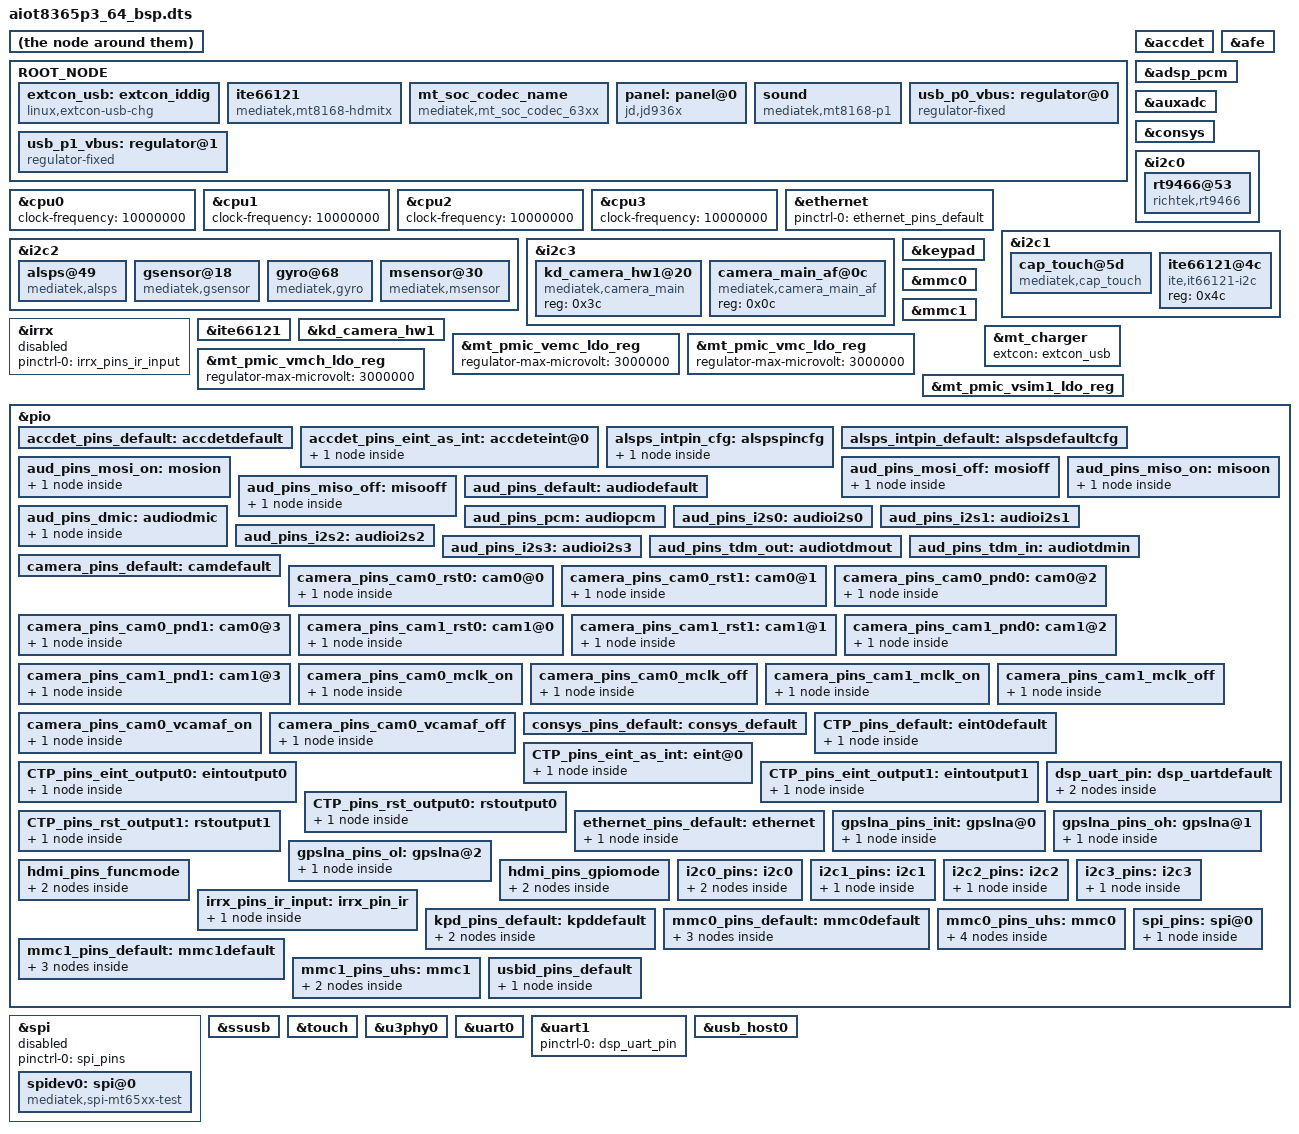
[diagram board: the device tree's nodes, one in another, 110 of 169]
/*
 * Copyright (c) 2018 MediaTek Inc.
 *
 * This program is free software; you can redistribute it and/or modify
 * it under the terms of the GNU General Public License version 2 as
 * published by the Free Software Foundation.
 *
 * This program is distributed in the hope that it will be useful,
 * MERCHANTABILITY or FITNESS FOR A PARTICULAR PURPOSE.  See the
 * GNU General Public License for more details.
 */

#include <generated/autoconf.h>
/dts-v1/;

/plugin/;
#include <dt-bindings/clock/mt8168-clk.h>
#include <dt-bindings/interrupt-controller/irq.h>
#include <dt-bindings/interrupt-controller/arm-gic.h>
#include <dt-bindings/pinctrl/mt8168-pinfunc.h>
#include <dt-bindings/gpio/gpio.h>
#include <dt-bindings/phy/phy.h>
#define ROOT_NODE &odm

ROOT_NODE {
	extcon_usb: extcon_iddig {
		compatible = "linux,extcon-usb-chg";
		id-gpio = <&pio 23 GPIO_ACTIVE_HIGH>;
		pinctrl-names = "default";
		pinctrl-0 = <&usbid_pins_default>;
	};

	ite66121: ite66121 {
		compatible = "mediatek,mt8168-hdmitx";
	};

	mt_soc_codec_name: mt_soc_codec_name {
		compatible = "mediatek,mt_soc_codec_63xx";
		use_hp_depop_flow = <0>; /* select 1: use, 0: not use */
		use_ul_260k = <0>; /* select 1: use, 0: not use */
	};

	panel: panel@0 {
		compatible = "jd,jd936x";
		gpio_lcd_pwr = <&pio 68 0>;
		gpio_lcd_rst = <&pio 20 0>;
		gpio_lcd_stb = <&pio 21 0>;
		reg-lcm-supply = <&mt_pmic_vsim1_ldo_reg>;
	};

	sound: sound {
		compatible = "mediatek,mt8168-p1";
		mediatek,platform = <&afe>;
		mediatek,adsp-platform = <&adsp_pcm>;
		pinctrl-names = "aud_mosi_on",
			"aud_mosi_off",
			"aud_miso_on",
			"aud_miso_off",
			"default",
			"aud_dmic",
			"aud_pcm",
			"aud_i2s0",
			"aud_i2s1",
			"aud_i2s2",
			"aud_i2s3",
			"aud_tdm_out",
			"aud_tdm_in";
		pinctrl-0 = <&aud_pins_mosi_on>;
		pinctrl-1 = <&aud_pins_mosi_off>;
		pinctrl-2 = <&aud_pins_miso_on>;
		pinctrl-3 = <&aud_pins_miso_off>;
		pinctrl-4 = <&aud_pins_default>;
		pinctrl-5 = <&aud_pins_dmic>;
		pinctrl-6 = <&aud_pins_pcm>;
		pinctrl-7 = <&aud_pins_i2s0>;
		pinctrl-8 = <&aud_pins_i2s1>;
		pinctrl-9 = <&aud_pins_i2s2>;
		pinctrl-10 = <&aud_pins_i2s3>;
		pinctrl-11 = <&aud_pins_tdm_out>;
		pinctrl-12 = <&aud_pins_tdm_in>;
		ext-amp1-gpio = <&pio 22 0>;
		ext-amp2-gpio = <&pio 22 0>;
		status = "okay";
	};

	usb_p0_vbus: regulator@0 {
		compatible = "regulator-fixed";
		regulator-name = "vbus0";
		regulator-min-microvolt = <5000000>;
		regulator-max-microvolt = <5000000>;
		gpio = <&pio 28 GPIO_ACTIVE_HIGH>;
		enable-active-high;
	};

	usb_p1_vbus: regulator@1 {
		compatible = "regulator-fixed";
		regulator-name = "vbus1";
		regulator-min-microvolt = <5000000>;
		regulator-max-microvolt = <5000000>;
		gpio = <&pio 134 GPIO_ACTIVE_HIGH>;
		enable-active-high;
		regulator-always-on;
	};
};

&accdet {
	accdet-mic-vol = <6>;
	headset-mode-setting = <0x500 0x500 1 0x1f0 0x800 0x800 0x20 0x44>;
	accdet-plugout-debounce = <1>;
	accdet-mic-mode = <1>;
	headset-eint-level-pol = <4>;
	headset-three-key-threshold = <0 80 220 400>;
	headset-three-key-threshold-CDD = <0 121 192 600>;
	headset-four-key-threshold = <0 58 121 192 400>;
	pinctrl-names = "default", "state_eint_as_int";
	pinctrl-0 = <&accdet_pins_default>;
	pinctrl-1 = <&accdet_pins_eint_as_int>;
	status = "okay";
};

&afe {
	mediatek,dl1-use-sram = <0x11221000 0x5000>;
	mediatek,dmic-iir-on = <1>;
	mediatek,dmic-irr-mode = <5>;
	mediatek,dmic-two-wire-mode = <1>;
	status = "okay";
};

&adsp_pcm {
	status = "okay";
};

&auxadc {
	status = "okay";
};

&consys {
	pinctrl-names = "default", "gps_lna_state_init",
			"gps_lna_state_oh", "gps_lna_state_ol";
	pinctrl-0 = <&consys_pins_default>;
	pinctrl-1 = <&gpslna_pins_init>;
	pinctrl-2 = <&gpslna_pins_oh>;
	pinctrl-3 = <&gpslna_pins_ol>;
	status = "okay";
};

&cpu0 {
	clock-frequency = <10000000>;
};

&cpu1 {
	clock-frequency = <10000000>;
};

&cpu2 {
	clock-frequency = <10000000>;
};

&cpu3 {
	clock-frequency = <10000000>;
};

&ethernet {
	status = "okay";
	pinctrl-names = "default";
	pinctrl-0 = <&ethernet_pins_default>;
};

&i2c0 {
	pinctrl-names = "default";
	pinctrl-0 = <&i2c0_pins>;
	clock-frequency = <100000>;
	status = "okay";
	rt9466@53 {
		compatible = "richtek,rt9466";
		reg = <0x53>;
		interrupt-parent = <&pio>;
		interrupts = <124 IRQ_TYPE_EDGE_FALLING>;
		rt-interrupt-names = "wdtmri", "chg_mivr", "chg_aiclmeasi",
			"chg_statci", "pwr_rdy";
		status = "okay";
		/*
		 * Charger name
		 * Main charger: primary_chg
		 * Slave charger: secondary_chg
		 */
		charger_name = "primary_chg";
		ichg = <2000000>; /* uA */
		aicr = <500000>;  /* uA */
		mivr = <4400000>; /* uV */
		cv = <4350000>;   /* uV */
		ieoc = <250000>;  /* uA */
		safety_timer = <12>;  /* hour */
		ircmp_resistor = <80000>; /* uohm */
		ircmp_vclamp = <96000>;  /* uV */
		en_te;
		/* en_wdt; */ /* remove it to support remote OTG wakeup */
		/* en_jeita; */
		/* en_irq_pulse; */
		/* ceb_invert; */
	};
};

&i2c1 {
	pinctrl-names = "default";
	pinctrl-0 = <&i2c1_pins>;
	clock-frequency = <100000>;
	status = "okay";

	cap_touch@5d {
		compatible = "mediatek,cap_touch";
		reg = <0x5d>;
		interrupt-parent = <&pio>;
		interrupts = <126 IRQ_TYPE_EDGE_RISING>;
		int-gpio = <&pio 126 0>;
		rst-gpio = <&pio 127 0>;
		status = "okay";
	};

	ite66121@4c {
		compatible = "ite,it66121-i2c";
		reg = <0x4c>;
		status = "okay";
	};
};

&i2c2 {
	pinctrl-names = "default";
	pinctrl-0 = <&i2c2_pins>;
	clock-frequency = <100000>;
	status = "okay";

	alsps@49 {
		compatible = "mediatek,alsps";
		pinctrl-names = "pin_default", "pin_cfg";
		pinctrl-0 = <&alsps_intpin_default>;
		pinctrl-1 = <&alsps_intpin_cfg>;

		interrupt-parent = <&pio>;
		interrupts = <117 IRQ_TYPE_LEVEL_LOW>;
		debounce = <117 0>;

		i2c_num = <2>;
		reg = <0x49>;
		polling_mode_ps = <0>;
		polling_mode_als = <1>;
		is_batch_supported_ps = <0>;
		is_batch_supported_als = <0>;
		is_batch_supported = <0>;
		power_id = <0xffff>;
		power_vol = <0>;
		firlen = <16>;

		/* epl259x */
		epl259x_addr = <0x49 0 0 0>;
		epl259x_level = <20 45 70 90 150 300 500 700 1150 2250 4500
				 8000 15000 30000 50000>;
		epl259x_value = <10 30 60 80 100 200 400 600 800 1500 3000
				 6000 10000 20000 40000 60000>;
		epl259x_thld_high =  <800>;
		epl259x_thld_low =  <500>;

		/* stk3x1x */
		stk3x1x_addr = <0x48 0 0 0>;
		stk3x1x_level = <5 9 36 59 82 132 205 273 500 845 1136 1545
				 2364 4655 6982>;
		stk3x1x_value = <30 40 80 130 180 290 450 600 1100 1860 2500
				 3400 5200 10240 10240 10240>;
		stk3x1x_thld_high = <1700>;
		stk3x1x_thld_low = <1500>;

		/* stk3x3x */
		stk3x3x_addr = <0x57 0 0 0>;
		stk3x3x_level = <10 80 160 240 400 560 700 900 1100 1300 1500
				 2364 3000 4655 6982>;
		stk3x3x_value = <0 80 160 260 450 600 750 1000 1250 1450 1700
				 2600 3300 5120 7680 10240>;
		stk3x3x_thld_high = <1700>;
		stk3x3x_thld_low = <1500>;

		status = "okay";
	};

	gsensor@18 {
		compatible = "mediatek,gsensor";
		reg = <0x18>;
		i2c_num = <2>;
		power_id = <0xffff>;
		power_vol = <0>;
		firlen = <16>;
		is_batch_supported = <0>;

		/* stk8baxx */
		stk8baxx_addr = <0x18 0 0 0>;
		stk8baxx_direction = <3>;

		/* mc34xx */
		mc34xx_addr = <0x4c 0 0 0>;
		mc34xx_direction = <3>;

		/* mpu6050g */
		mpu6050g_addr = <0x68 0 0 0>;
		mpu6050g_direction = <4>;

		status = "okay";
	};

	gyro@68 {
		compatible = "mediatek,gyro";
		reg = <0x68>;
		i2c_num = <2>;
		power_id = <0xffff>;
		power_vol = <0>;
		firlen = <0>;
		is_batch_supported = <0>;

		/* mpu6050gy */
		mpu6050gy_addr = <0x68 0 0 0>;
		mpu6050gy_direction = <4>;

		status = "okay";
	};

	msensor@30 {
		compatible = "mediatek,msensor";
		reg = <0x30>;
		i2c_num = <2>;
		power_id = <0xffff>;
		power_vol = <0>;
		is_batch_supported = <0>;

		/* mmc3416x */
		mmc3416x_addr = <0x30 0 0 0>;
		mmc3416x_direction = <2>;

		/* mmc3630x */
		mmc3630x_addr = <0x30 0 0 0>;
		mmc3630x_direction = <2>;

		status = "okay";
	};
};

&i2c3 {
	pinctrl-names = "default";
	pinctrl-0 = <&i2c3_pins>;
	clock-frequency = <100000>;
	status = "okay";

	kd_camera_hw1@20 {
		compatible = "mediatek,camera_main";
		reg = <0x3c>;
	};

	camera_main_af@0c {
		compatible = "mediatek,camera_main_af";
		reg = <0x0c>;
	};
};

&irrx {
	pinctrl-names = "default";
	pinctrl-0 = <&irrx_pins_ir_input>;
	status = "disabled";
};

&ite66121 {
	pinctrl-names = "hdmi_poweron", "hdmi_poweroff";
	pinctrl-0 = <&hdmi_pins_funcmode>;
	pinctrl-1 = <&hdmi_pins_gpiomode>;
	hdmi_power_gpios = <&pio 79 0>;
	not_use_pmic_supply;
	status = "okay";
};

&keypad {
	pinctrl-names = "default";
	pinctrl-0 = <&kpd_pins_default>;
	status = "okay";
	mediatek,kpd-key-debounce = <1024>;
	mediatek,kpd-sw-pwrkey = <116>;
	mediatek,kpd-hw-pwrkey = <1>;
	mediatek,kpd-sw-rstkey  = <115>;
	mediatek,kpd-hw-rstkey = <3>;
	mediatek,kpd-use-extend-type = <0>;
	/*HW Keycode [0~3] -> Linux Keycode*/
	mediatek,kpd-hw-map-num = <72>;
	mediatek,kpd-hw-init-map =
			<114 0 0 0 0 0 0 0 0 0 0 0 0
			 0 0 0 0 0 0 0 0 0 0 0 0 0 0 0 0 0 0 0 0 0 0 0 0
			 0 0 0 0 0 0 0 0 0 0 0 0 0 0 0 0 0 0 0 0 0 0 0 0
			 0 0 0 0 0 0 0 0 0 0 0 >;
	mediatek,kpd-pwrkey-eint-gpio = <0>;
	mediatek,kpd-pwkey-gpio-din  = <0>;
	mediatek,kpd-hw-dl-key0 = <0>;
	mediatek,kpd-hw-dl-key1 = <3>;
	mediatek,kpd-hw-dl-key2 = <1>;
	mediatek,kpd-hw-recovery-key = <0>;
	mediatek,kpd-hw-factory-key  = <3>;
};


&kd_camera_hw1 {
	/* main cam power supply */
	vcama-supply = <&mt_pmic_vcama_ldo_reg>;         /* AVDD */
	vcamd-supply = <&mt_pmic_vcamd_ldo_reg>;         /* DVDD */
	vcamio-supply = <&mt_pmic_vcamio_ldo_reg>;       /* DOVDD */

	/* sub cam power supply */
	vcama_sub-supply = <&mt_pmic_vcama_ldo_reg>;         /* AVDD */
	vcamd_sub-supply = <&mt_pmic_vcamd_ldo_reg>;         /* DVDD */
	vcamio_sub-supply = <&mt_pmic_vcamio_ldo_reg>;       /* DOVDD */

	pinctrl-names = "default",
			"cam0_rst0", "cam0_rst1", "cam0_pnd0", "cam0_pnd1",
			"cam1_rst0", "cam1_rst1", "cam1_pnd0", "cam1_pnd1",
			"cam0_mclk_on", "cam0_mclk_off",
			"cam1_mclk_on", "cam1_mclk_off",
			"cam_ldo_vcamaf_1", "cam_ldo_vcamaf_0";

	pinctrl-0 = <&camera_pins_default>;
	pinctrl-1 = <&camera_pins_cam0_rst0>;
	pinctrl-2 = <&camera_pins_cam0_rst1>;
	pinctrl-3 = <&camera_pins_cam0_pnd0>;
	pinctrl-4 = <&camera_pins_cam0_pnd1>;
	pinctrl-5 = <&camera_pins_cam1_rst0>;
	pinctrl-6 = <&camera_pins_cam1_rst1>;
	pinctrl-7 = <&camera_pins_cam1_pnd0>;
	pinctrl-8 = <&camera_pins_cam1_pnd1>;
	pinctrl-9 = <&camera_pins_cam0_mclk_on>;
	pinctrl-10 = <&camera_pins_cam0_mclk_off>;
	pinctrl-11 = <&camera_pins_cam1_mclk_on>;
	pinctrl-12 = <&camera_pins_cam1_mclk_off>;
	pinctrl-13 = <&camera_pins_cam0_vcamaf_on>;
	pinctrl-14 = <&camera_pins_cam0_vcamaf_off>;

	status = "okay";
};

&mmc0 {
	status = "okay";
	pinctrl-names = "default", "state_uhs";
	pinctrl-0 = <&mmc0_pins_default>;
	pinctrl-1 = <&mmc0_pins_uhs>;
	bus-width = <8>;
	max-frequency = <200000000>;
	cap-mmc-highspeed;
	mmc-hs200-1_8v;
	mmc-hs400-1_8v;
	cap-cqe;
	cap-cqe_dcmd;
	hs400-ds-delay = <0x12012>;
	vmmc-supply = <&mt_pmic_vemc_ldo_reg>;
	vqmmc-supply = <&mt_pmic_vio18_ldo_reg>;
	assigned-clocks = <&topckgen CLK_TOP_MSDC50_0_SEL>;
	assigned-clock-parents = <&topckgen CLK_TOP_MSDCPLL>;
	non-removable;
	no-sd;
	no-sdio;
};

&mmc1 {
	status = "okay";
	pinctrl-names = "default", "state_uhs";
	pinctrl-0 = <&mmc1_pins_default>;
	pinctrl-1 = <&mmc1_pins_uhs>;
	bus-width = <4>;
	max-frequency = <200000000>;
	cap-sd-highspeed;
	sd-uhs-sdr50;
	sd-uhs-sdr104;
	cd-gpios = <&pio 125 GPIO_ACTIVE_LOW>;
	vmmc-supply = <&mt_pmic_vmch_ldo_reg>;
	vqmmc-supply = <&mt_pmic_vmc_ldo_reg>;
	no-mmc;
	no-sdio;
};

&mt_charger {
	extcon = <&extcon_usb>;
	status = "okay";
};

&mt_pmic_vemc_ldo_reg {
	regulator-max-microvolt = <3000000>;
};

&mt_pmic_vmc_ldo_reg {
	regulator-max-microvolt = <3000000>;
};

&mt_pmic_vmch_ldo_reg {
	regulator-max-microvolt = <3000000>;
};

&mt_pmic_vsim1_ldo_reg {
	regulator-min-microvolt = <1800000>;
	regulator-max-microvolt = <1800000>;
	regulator-boot-on;
};

&pio {
	pinctrl-names = "default";

	accdet_pins_default: accdetdefault {
	};

	accdet_pins_eint_as_int: accdeteint@0 {
		pins_cmd_dat {
			pinmux = <MT8168_PIN_70_CMDAT2__FUNC_GPIO70>;
			slew-rate = <0>;
			bias-disable;
		};
	};

	alsps_intpin_cfg: alspspincfg {
		pins_cmd_dat {
			pinmux = <MT8168_PIN_117_DMIC0_CLK__FUNC_GPIO117>;
			slew-rate = <0>;
			bias-pull-up = <00>;
		};
	};

	alsps_intpin_default: alspsdefaultcfg {
	};

	aud_pins_mosi_on: mosion {
		pins_cmd_dat {
		pinmux = <MT8168_PIN_49_AUD_CLK_MOSI__FUNC_AUD_CLK_MOSI>,
			 <MT8168_PIN_50_AUD_SYNC_MOSI__FUNC_AUD_SYNC_MOSI>,
			 <MT8168_PIN_51_AUD_DAT_MOSI0__FUNC_AUD_DAT_MOSI0>,
			 <MT8168_PIN_52_AUD_DAT_MOSI1__FUNC_AUD_DAT_MOSI1>;
		drive-strength = <MTK_DRIVE_6mA>;
		};
	};

	aud_pins_mosi_off: mosioff {
		pins_cmd_dat {
		pinmux = <MT8168_PIN_49_AUD_CLK_MOSI__FUNC_GPIO49>,
			 <MT8168_PIN_50_AUD_SYNC_MOSI__FUNC_GPIO50>,
			 <MT8168_PIN_51_AUD_DAT_MOSI0__FUNC_GPIO51>,
			 <MT8168_PIN_52_AUD_DAT_MOSI1__FUNC_GPIO52>;
		input-enable;
		bias-pull-down;
		drive-strength = <MTK_DRIVE_2mA>;
		};
	};

	aud_pins_miso_on: misoon {
		pins_cmd_dat {
		pinmux = <MT8168_PIN_53_AUD_CLK_MISO__FUNC_AUD_CLK_MISO>,
			 <MT8168_PIN_54_AUD_SYNC_MISO__FUNC_AUD_SYNC_MISO>,
			 <MT8168_PIN_55_AUD_DAT_MISO0__FUNC_AUD_DAT_MISO0>,
			 <MT8168_PIN_56_AUD_DAT_MISO1__FUNC_AUD_DAT_MISO1>;
		drive-strength = <MTK_DRIVE_6mA>;
		};
	};

	aud_pins_miso_off: misooff {
		pins_cmd_dat {
		pinmux = <MT8168_PIN_53_AUD_CLK_MISO__FUNC_GPIO53>,
			 <MT8168_PIN_54_AUD_SYNC_MISO__FUNC_GPIO54>,
			 <MT8168_PIN_55_AUD_DAT_MISO0__FUNC_GPIO55>,
			 <MT8168_PIN_56_AUD_DAT_MISO1__FUNC_GPIO56>;
		input-enable;
		bias-pull-down;
		drive-strength = <MTK_DRIVE_2mA>;
		};
	};

	aud_pins_default: audiodefault {
	};

	aud_pins_dmic: audiodmic {
		pins_cmd_dat {
		pinmux = <MT8168_PIN_117_DMIC0_CLK__FUNC_DMIC0_CLK>,
			 <MT8168_PIN_118_DMIC0_DAT0__FUNC_DMIC0_DAT0>,
			 <MT8168_PIN_119_DMIC0_DAT1__FUNC_DMIC0_DAT1>;
		};
	};

	aud_pins_pcm: audiopcm {
	};

	aud_pins_i2s0: audioi2s0 {
	};

	aud_pins_i2s1: audioi2s1 {
	};

	aud_pins_i2s2: audioi2s2 {
	};

	aud_pins_i2s3: audioi2s3 {
	};

	aud_pins_tdm_out: audiotdmout {
	};

	aud_pins_tdm_in: audiotdmin {
	};

	camera_pins_default: camdefault {
	};

	camera_pins_cam0_rst0: cam0@0 {
		pins_cmd_dat {
			pinmux = <MT8168_PIN_76_CMDAT8__FUNC_GPIO76>;
			slew-rate = <1>; /*direction 0:in, 1:out*/
			output-low;
		};
	};

	camera_pins_cam0_rst1: cam0@1 {
		pins_cmd_dat {
			pinmux = <MT8168_PIN_76_CMDAT8__FUNC_GPIO76>;
			slew-rate = <1>;
			output-high;
		};
	};

	camera_pins_cam0_pnd0: cam0@2 {
		pins_cmd_dat {
			pinmux = <MT8168_PIN_77_CMDAT9__FUNC_GPIO77>;
			slew-rate = <1>;
			output-low;
		};
	};

	camera_pins_cam0_pnd1: cam0@3 {
		pins_cmd_dat {
			pinmux = <MT8168_PIN_77_CMDAT9__FUNC_GPIO77>;
			slew-rate = <1>;
			output-high;
		};
	};

	camera_pins_cam1_rst0: cam1@0 {
		pins_cmd_dat {
			pinmux = <MT8168_PIN_76_CMDAT8__FUNC_GPIO76>;
			slew-rate = <1>; /*direction 0:in, 1:out*/
			output-low;
		};
	};

	camera_pins_cam1_rst1: cam1@1 {
		pins_cmd_dat {
			pinmux = <MT8168_PIN_74_CMDAT6__FUNC_GPIO74>;
			slew-rate = <1>;
			output-high;
		};
	};

	camera_pins_cam1_pnd0: cam1@2 {
		pins_cmd_dat {
			pinmux = <MT8168_PIN_75_CMDAT7__FUNC_GPIO75>;
			slew-rate = <1>;
			output-low;
		};
	};

	camera_pins_cam1_pnd1: cam1@3 {
		pins_cmd_dat {
			pinmux = <MT8168_PIN_75_CMDAT7__FUNC_GPIO75>;
			slew-rate = <1>;
			output-high;
		};
	};

	camera_pins_cam0_mclk_on: camera_pins_cam0_mclk_on {
		pins_cmd_dat {
			pinmux = <MT8168_PIN_65_CMMCLK0__FUNC_CMMCLK0>;
		};
	};

	camera_pins_cam0_mclk_off: camera_pins_cam0_mclk_off {
		pins_cmd_dat {
			pinmux = <MT8168_PIN_65_CMMCLK0__FUNC_GPIO65>;
		};
	};

	camera_pins_cam1_mclk_on: camera_pins_cam1_mclk_on {
		pins_cmd_dat {
			pinmux = <MT8168_PIN_66_CMMCLK1__FUNC_CMMCLK1>;
		};
	};

	camera_pins_cam1_mclk_off: camera_pins_cam1_mclk_off {
		pins_cmd_dat {
			pinmux = <MT8168_PIN_66_CMMCLK1__FUNC_GPIO66>;
		};
	};

	camera_pins_cam0_vcamaf_on: camera_pins_cam0_vcamaf_on {
		pins_cmd_dat {
			pinmux = <MT8168_PIN_73_CMDAT5__FUNC_GPIO73>;
			slew-rate = <1>;
			output-high;
		};
	};
	camera_pins_cam0_vcamaf_off: camera_pins_cam0_vcamaf_off {
		pins_cmd_dat {
			pinmux = <MT8168_PIN_73_CMDAT5__FUNC_GPIO73>;
			slew-rate = <1>;
			output-low;
		};
	};

	consys_pins_default: consys_default {
	};

	CTP_pins_default: eint0default {
		pins_cmd_dat {
			pinmux = <MT8168_PIN_126_DMIC3_CLK__FUNC_GPIO126>;
			slew-rate = <0>;
			bias-disable;
		};
	};

	CTP_pins_eint_as_int: eint@0 {
		pins_cmd_dat {
			pinmux = <MT8168_PIN_126_DMIC3_CLK__FUNC_GPIO126>;
			slew-rate = <0>;
			bias-disable;
		};
	};

	CTP_pins_eint_output0: eintoutput0 {
		pins_cmd_dat {
			pinmux = <MT8168_PIN_126_DMIC3_CLK__FUNC_GPIO126>;
			slew-rate = <1>;
			output-low;
		};
	};

	CTP_pins_eint_output1: eintoutput1 {
		pins_cmd_dat {
			pinmux = <MT8168_PIN_126_DMIC3_CLK__FUNC_GPIO126>;
			slew-rate = <1>;
			output-high;
		};
	};

	CTP_pins_rst_output0: rstoutput0 {
		pins_cmd_dat {
			pinmux = <MT8168_PIN_127_DMIC3_DAT0__FUNC_GPIO127>;
			slew-rate = <1>;
			output-low;
		};
	};

	CTP_pins_rst_output1: rstoutput1 {
		pins_cmd_dat {
			pinmux = <MT8168_PIN_127_DMIC3_DAT0__FUNC_GPIO127>;
			slew-rate = <1>;
			output-high;
		};
	};

	dsp_uart_pin: dsp_uartdefault {
		pins_rx {
			pinmux = <MT8168_PIN_37_URXD1__FUNC_DSP_URXD0>;
			input-enable;
			bias-pull-up;
		};
		pins_tx {
			pinmux = <MT8168_PIN_38_UTXD1__FUNC_DSP_UTXD0>;
		};
	};

	ethernet_pins_default: ethernet {
		pins_ethernet {
			pinmux = <MT8168_PIN_0_GPIO0__FUNC_EXT_TXD0>,
				 <MT8168_PIN_1_GPIO1__FUNC_EXT_TXD1>,
				 <MT8168_PIN_2_GPIO2__FUNC_EXT_TXD2>,
				 <MT8168_PIN_3_GPIO3__FUNC_EXT_TXD3>,
				 <MT8168_PIN_4_GPIO4__FUNC_EXT_TXC>,
				 <MT8168_PIN_5_GPIO5__FUNC_EXT_RXER>,
				 <MT8168_PIN_6_GPIO6__FUNC_EXT_RXC>,
				 <MT8168_PIN_7_GPIO7__FUNC_EXT_RXDV>,
				 <MT8168_PIN_8_GPIO8__FUNC_EXT_RXD0>,
				 <MT8168_PIN_9_GPIO9__FUNC_EXT_RXD1>,
				 <MT8168_PIN_10_GPIO10__FUNC_EXT_RXD2>,
				 <MT8168_PIN_11_GPIO11__FUNC_EXT_RXD3>,
				 <MT8168_PIN_12_GPIO12__FUNC_EXT_TXEN>,
				 <MT8168_PIN_13_GPIO13__FUNC_EXT_COL>,
				 <MT8168_PIN_14_GPIO14__FUNC_EXT_MDIO>,
				 <MT8168_PIN_15_GPIO15__FUNC_EXT_MDC>;
		};
	};

	gpslna_pins_init: gpslna@0 {
		pins_cmd_dat {
			pinmux = <MT8168_PIN_69_CMDAT1__FUNC_GPIO69>;
			slew-rate = <0>;
			bias-disable;
			output-low;
		};
	};

	gpslna_pins_oh: gpslna@1 {
		pins_cmd_dat {
			pinmux = <MT8168_PIN_69_CMDAT1__FUNC_GPIO69>;
			slew-rate = <1>;
			output-high;
		};
	};

	gpslna_pins_ol: gpslna@2 {
		pins_cmd_dat {
			pinmux = <MT8168_PIN_69_CMDAT1__FUNC_GPIO69>;
			slew-rate = <1>;
			output-low;
		};
	};

	hdmi_pins_funcmode: hdmi_pins_funcmode {
		pins_cmd_dat {
			pinmux = <MT8168_PIN_0_GPIO0__FUNC_DPI_D0>,
				 <MT8168_PIN_1_GPIO1__FUNC_DPI_D1>,
				 <MT8168_PIN_2_GPIO2__FUNC_DPI_D2>,
				 <MT8168_PIN_3_GPIO3__FUNC_DPI_D3>,
				 <MT8168_PIN_4_GPIO4__FUNC_DPI_D4>,
				 <MT8168_PIN_5_GPIO5__FUNC_DPI_D5>,
				 <MT8168_PIN_6_GPIO6__FUNC_DPI_D6>,
				 <MT8168_PIN_7_GPIO7__FUNC_DPI_D7>,
				 <MT8168_PIN_8_GPIO8__FUNC_DPI_D8>,
				 <MT8168_PIN_9_GPIO9__FUNC_DPI_D9>,
				 <MT8168_PIN_10_GPIO10__FUNC_DPI_D10>,
				 <MT8168_PIN_11_GPIO11__FUNC_DPI_D11>,
				 <MT8168_PIN_12_GPIO12__FUNC_DPI_DE>,
				 <MT8168_PIN_13_GPIO13__FUNC_DPI_VSYNC>,
				 <MT8168_PIN_14_GPIO14__FUNC_DPI_CK>,
				 <MT8168_PIN_15_GPIO15__FUNC_DPI_HSYNC>,
				 <MT8168_PIN_16_GPIO16__FUNC_DPI_D12>,
				 <MT8168_PIN_17_GPIO17__FUNC_DPI_D13>,
				 <MT8168_PIN_18_GPIO18__FUNC_DPI_D14>,
				 <MT8168_PIN_110_PCM_CLK__FUNC_DPI_D15>,
				 <MT8168_PIN_111_PCM_SYNC__FUNC_DPI_D16>,
				 <MT8168_PIN_112_PCM_RX__FUNC_DPI_D17>,
				 <MT8168_PIN_113_PCM_TX__FUNC_DPI_D18>,
				 <MT8168_PIN_80_MSDC2_CMD__FUNC_DPI_D19>,
				 <MT8168_PIN_81_MSDC2_CLK__FUNC_DPI_D20>,
				 <MT8168_PIN_82_MSDC2_DAT0__FUNC_DPI_D21>,
				 <MT8168_PIN_83_MSDC2_DAT1__FUNC_DPI_D22>,
				 <MT8168_PIN_84_MSDC2_DAT2__FUNC_DPI_D23>,
				 <MT8168_PIN_114_I2S_DATA_IN__FUNC_I2S3_DO>,
				 <MT8168_PIN_115_I2S_LRCK__FUNC_I2S3_LRCK>,
				 <MT8168_PIN_116_I2S_BCK__FUNC_I2S3_BCK>;
		};
		hdmi_5v_pin_on {
			pinmux = <MT8168_PIN_27_SPI_CK__FUNC_GPIO27>;
			slew-rate = <1>;
			output-high;
		};
	};

	hdmi_pins_gpiomode: hdmi_pins_gpiomode {
		pins_cmd_dat {
			pinmux = <MT8168_PIN_0_GPIO0__FUNC_GPIO0>,
				 <MT8168_PIN_1_GPIO1__FUNC_GPIO1>,
				 <MT8168_PIN_2_GPIO2__FUNC_GPIO2>,
				 <MT8168_PIN_3_GPIO3__FUNC_GPIO3>,
				 <MT8168_PIN_4_GPIO4__FUNC_GPIO4>,
				 <MT8168_PIN_5_GPIO5__FUNC_GPIO5>,
				 <MT8168_PIN_6_GPIO6__FUNC_GPIO6>,
				 <MT8168_PIN_7_GPIO7__FUNC_GPIO7>,
				 <MT8168_PIN_8_GPIO8__FUNC_GPIO8>,
				 <MT8168_PIN_9_GPIO9__FUNC_GPIO9>,
				 <MT8168_PIN_10_GPIO10__FUNC_GPIO10>,
				 <MT8168_PIN_11_GPIO11__FUNC_GPIO11>,
				 <MT8168_PIN_12_GPIO12__FUNC_GPIO12>,
				 <MT8168_PIN_13_GPIO13__FUNC_GPIO13>,
				 <MT8168_PIN_14_GPIO14__FUNC_GPIO14>,
				 <MT8168_PIN_15_GPIO15__FUNC_GPIO15>,
				 <MT8168_PIN_16_GPIO16__FUNC_GPIO16>,
				 <MT8168_PIN_17_GPIO17__FUNC_GPIO17>,
				 <MT8168_PIN_18_GPIO18__FUNC_GPIO18>,
				 <MT8168_PIN_110_PCM_CLK__FUNC_GPIO110>,
				 <MT8168_PIN_111_PCM_SYNC__FUNC_GPIO111>,
				 <MT8168_PIN_112_PCM_RX__FUNC_GPIO112>,
				 <MT8168_PIN_113_PCM_TX__FUNC_GPIO113>,
				 <MT8168_PIN_80_MSDC2_CMD__FUNC_GPIO80>,
				 <MT8168_PIN_81_MSDC2_CLK__FUNC_GPIO81>,
				 <MT8168_PIN_82_MSDC2_DAT0__FUNC_GPIO82>,
				 <MT8168_PIN_83_MSDC2_DAT1__FUNC_GPIO83>,
				 <MT8168_PIN_84_MSDC2_DAT2__FUNC_GPIO84>,
				 <MT8168_PIN_114_I2S_DATA_IN__FUNC_GPIO114>,
				 <MT8168_PIN_115_I2S_LRCK__FUNC_GPIO115>,
				 <MT8168_PIN_116_I2S_BCK__FUNC_GPIO116>;
		};
		hdmi_5v_pin_off {
			pinmux = <MT8168_PIN_27_SPI_CK__FUNC_GPIO27>;
			slew-rate = <0>;
		};
	};

	i2c0_pins: i2c0 {
		pins_bus {
			pinmux = <MT8168_PIN_57_SDA0__FUNC_SDA0_0>,
				 <MT8168_PIN_58_SCL0__FUNC_SCL0_0>;
			bias-pull-up;
		};
		pins_bus1 {
			pinmux = <MT8168_PIN_124_DMIC2_DAT0__FUNC_GPIO124>;
			input-enable;
			bias-pull-up;
		};
	};

	i2c1_pins: i2c1 {
		pins_bus {
			pinmux = <MT8168_PIN_59_SDA1__FUNC_SDA1_0>,
				 <MT8168_PIN_60_SCL1__FUNC_SCL1_0>;
			bias-pull-up;
		};
	};

	i2c2_pins: i2c2 {
		pins_bus {
			pinmux = <MT8168_PIN_61_SDA2__FUNC_SDA2_0>,
				 <MT8168_PIN_62_SCL2__FUNC_SCL2_0>;
			bias-pull-up;
		};
	};

	i2c3_pins: i2c3 {
		pins_bus {
			pinmux = <MT8168_PIN_63_SDA3__FUNC_SDA3_0>,
				 <MT8168_PIN_64_SCL3__FUNC_SCL3_0>;
			bias-pull-up;
		};
	};

	irrx_pins_ir_input: irrx_pin_ir {
		pins_cmd_dat {
			pinmux = <MT8168_PIN_15_GPIO15__FUNC_IRRX>;
			bias-disable;
		};
	};

	kpd_pins_default: kpddefault {
		pins_cols {
			pinmux = <MT8168_PIN_24_KPCOL0__FUNC_KPCOL0>,
				 <MT8168_PIN_25_KPCOL1__FUNC_KPCOL1>;
			input-enable;
			bias-pull-up = <MTK_PUPD_SET_R1R0_01>;
		};

		pins_rows {
			pinmux = <MT8168_PIN_22_KPROW0__FUNC_KPROW0>;
			output-low;
			bias-disable;
		};
	};

	mmc0_pins_default: mmc0default {
		pins_clk {
			pinmux = <MT8168_PIN_99_MSDC0_CLK__FUNC_MSDC0_CLK>;
			bias-pull-down;
		};

		pins_cmd_dat {
			pinmux = <MT8168_PIN_103_MSDC0_DAT0__FUNC_MSDC0_DAT0>,
				 <MT8168_PIN_102_MSDC0_DAT1__FUNC_MSDC0_DAT1>,
				 <MT8168_PIN_101_MSDC0_DAT2__FUNC_MSDC0_DAT2>,
				 <MT8168_PIN_100_MSDC0_DAT3__FUNC_MSDC0_DAT3>,
				 <MT8168_PIN_96_MSDC0_DAT4__FUNC_MSDC0_DAT4>,
				 <MT8168_PIN_95_MSDC0_DAT5__FUNC_MSDC0_DAT5>,
				 <MT8168_PIN_94_MSDC0_DAT6__FUNC_MSDC0_DAT6>,
				 <MT8168_PIN_93_MSDC0_DAT7__FUNC_MSDC0_DAT7>,
				 <MT8168_PIN_98_MSDC0_CMD__FUNC_MSDC0_CMD>;
			input-enable;
			bias-pull-up;
		};

		pins_rst {
			pinmux = <MT8168_PIN_97_MSDC0_RSTB__FUNC_MSDC0_RSTB>;
			bias-pull-up;
		};
	};

	mmc0_pins_uhs: mmc0 {
		pins_clk {
			pinmux = <MT8168_PIN_99_MSDC0_CLK__FUNC_MSDC0_CLK>;
			drive-strength = <MTK_DRIVE_6mA>;
			bias-pull-down = <MTK_PUPD_SET_R1R0_01>;
		};

		pins_cmd_dat {
			pinmux = <MT8168_PIN_103_MSDC0_DAT0__FUNC_MSDC0_DAT0>,
				 <MT8168_PIN_102_MSDC0_DAT1__FUNC_MSDC0_DAT1>,
				 <MT8168_PIN_101_MSDC0_DAT2__FUNC_MSDC0_DAT2>,
				 <MT8168_PIN_100_MSDC0_DAT3__FUNC_MSDC0_DAT3>,
				 <MT8168_PIN_96_MSDC0_DAT4__FUNC_MSDC0_DAT4>,
				 <MT8168_PIN_95_MSDC0_DAT5__FUNC_MSDC0_DAT5>,
				 <MT8168_PIN_94_MSDC0_DAT6__FUNC_MSDC0_DAT6>,
				 <MT8168_PIN_93_MSDC0_DAT7__FUNC_MSDC0_DAT7>,
				 <MT8168_PIN_98_MSDC0_CMD__FUNC_MSDC0_CMD>;
			input-enable;
			drive-strength = <MTK_DRIVE_6mA>;
			bias-pull-up = <MTK_PUPD_SET_R1R0_01>;
		};

		pins_ds {
			pinmux = <MT8168_PIN_104_MSDC0_DSL__FUNC_MSDC0_DSL>;
			drive-strength = <MTK_DRIVE_6mA>;
			bias-pull-down = <MTK_PUPD_SET_R1R0_10>;
		};

		pins_rst {
			pinmux = <MT8168_PIN_97_MSDC0_RSTB__FUNC_MSDC0_RSTB>;
			bias-pull-up;
		};
	};

	mmc1_pins_default: mmc1default {
		pins_clk {
			pinmux = <MT8168_PIN_88_MSDC1_CLK__FUNC_MSDC1_CLK>;
			drive-strength = <MTK_DRIVE_4mA>;
			bias-pull-down = <MTK_PUPD_SET_R1R0_10>;
		};

		pins_cmd_dat {
			pinmux = <MT8168_PIN_89_MSDC1_DAT0__FUNC_MSDC1_DAT0>,
				 <MT8168_PIN_90_MSDC1_DAT1__FUNC_MSDC1_DAT1>,
				 <MT8168_PIN_91_MSDC1_DAT2__FUNC_MSDC1_DAT2>,
				 <MT8168_PIN_92_MSDC1_DAT3__FUNC_MSDC1_DAT3>,
				 <MT8168_PIN_87_MSDC1_CMD__FUNC_MSDC1_CMD>;
			input-enable;
			drive-strength = <MTK_DRIVE_4mA>;
			bias-pull-up = <MTK_PUPD_SET_R1R0_01>;
		};

		pins_insert {
			pinmux = <MT8168_PIN_125_DMIC2_DAT1__FUNC_GPIO125>;
			bias-pull-up;
		};
	};

	mmc1_pins_uhs: mmc1 {
		pins_clk {
			pinmux = <MT8168_PIN_88_MSDC1_CLK__FUNC_MSDC1_CLK>;
			drive-strength = <MTK_DRIVE_6mA>;
			bias-pull-down = <MTK_PUPD_SET_R1R0_10>;
		};

		pins_cmd_dat {
			pinmux = <MT8168_PIN_89_MSDC1_DAT0__FUNC_MSDC1_DAT0>,
				 <MT8168_PIN_90_MSDC1_DAT1__FUNC_MSDC1_DAT1>,
				 <MT8168_PIN_91_MSDC1_DAT2__FUNC_MSDC1_DAT2>,
				 <MT8168_PIN_92_MSDC1_DAT3__FUNC_MSDC1_DAT3>,
				 <MT8168_PIN_87_MSDC1_CMD__FUNC_MSDC1_CMD>;
			input-enable;
			drive-strength = <MTK_DRIVE_6mA>;
			bias-pull-up = <MTK_PUPD_SET_R1R0_01>;
		};
	};

	spi_pins: spi@0 {
		pins_spi {
			pinmux = <MT8168_PIN_26_SPI_CS__FUNC_SPI_CSB>,
				 <MT8168_PIN_27_SPI_CK__FUNC_SPI_CLK>,
				 <MT8168_PIN_28_SPI_MI__FUNC_SPI_MI>,
				 <MT8168_PIN_29_SPI_MO__FUNC_SPI_MO>;
			bias-disable;
		};
	};

	usbid_pins_default: usbid_pins_default {
		pins_cmd1_dat {
			pinmux = <MT8168_PIN_23_KPROW1__FUNC_GPIO23>;
			input-enable;
			slew-rate = <0>;
			bias-pull-up = <MTK_PUPD_SET_R1R0_01>;
		};
	};
};

&spi {
	pinctrl-names = "default";
	pinctrl-0 = <&spi_pins>;
	status = "disable";

	spidev0: spi@0 {
		compatible = "mediatek,spi-mt65xx-test";
		reg = <0>;
		spi-max-frequency = <1000000>;
	};
};

&ssusb {
	phys = <&u2port0 PHY_TYPE_USB2>,
	       <&u2port1 PHY_TYPE_USB2>;
	vusb33-supply = <&mt_pmic_vusb33_ldo_reg>;
	vbus-supply = <&usb_p0_vbus>;
	extcon = <&extcon_usb>;
	dr_mode = "otg";
	status="okay";
};

&touch {
	vtouch-supply = <&mt_pmic_vldo28_ldo_reg>;
	tpd-resolution = <800 1280>;
	use-tpd-button = <0>;
	tpd-key-num = <3>;
	tpd-key-local= <139 172 158 0>;
	tpd-key-dim-local = <90 883 100 40 230 883
		100 40 370 883 100 40 0 0 0 0>;
	tpd-max-touch-num = <5>;
	tpd-filter-enable = <1>;
	tpd-filter-pixel-density = <124>;
	tpd-filter-custom-prameters = <0 0 0 0 0 0 0 0 0 0 0 0>;
	tpd-filter-custom-speed = <0 0 0>;
	pinctrl-names = "default", "state_eint_as_int",
		"state_eint_output0", "state_eint_output1",
		"state_rst_output0", "state_rst_output1";
	pinctrl-0 = <&CTP_pins_default>;
	pinctrl-1 = <&CTP_pins_eint_as_int>;
	pinctrl-2 = <&CTP_pins_eint_output0>;
	pinctrl-3 = <&CTP_pins_eint_output1>;
	pinctrl-4 = <&CTP_pins_rst_output0>;
	pinctrl-5 = <&CTP_pins_rst_output1>;
	status = "okay";
};

&u3phy0 {
	status="okay";
};

&uart0 {
	status="okay";
};

&uart1 {
	pinctrl-names = "default";
	pinctrl-0 = <&dsp_uart_pin>;
	status="okay";
};

&usb_host0 {
	vusb33-supply = <&mt_pmic_vusb33_ldo_reg>;
	vbus-supply = <&usb_p1_vbus>;
	status = "okay";
};

